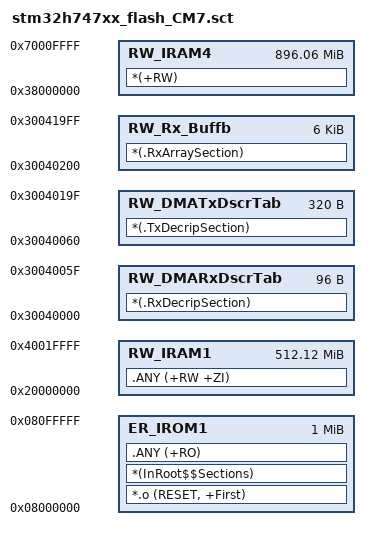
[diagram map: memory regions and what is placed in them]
; *************************************************************
; *** Scatter-Loading Description File generated by uVision ***
; *************************************************************

LR_IROM1 0x08000000 0x00100000  {    ; load region size_region
  ER_IROM1 0x08000000 0x00100000  {  ; load address = execution address
   *.o (RESET, +First)
   *(InRoot$$Sections)
   .ANY (+RO)
  }
  RW_IRAM1 0x20000000 0x20020000{  ; RW data
   .ANY (+RW +ZI)
  } 
  RW_DMARxDscrTab 0x30040000 0x60 {
  *(.RxDecripSection)
  }
  RW_DMATxDscrTab 0x30040060 0x140 {
  *(.TxDecripSection)
  }
  RW_Rx_Buffb 0x30040200 0x1800 {
  *(.RxArraySection)
  }
  RW_IRAM4 0x38000000 0x38010000{  ; RW data
   *(+RW)
;   *(.ARM.__at_0x38000000)
  }
}
